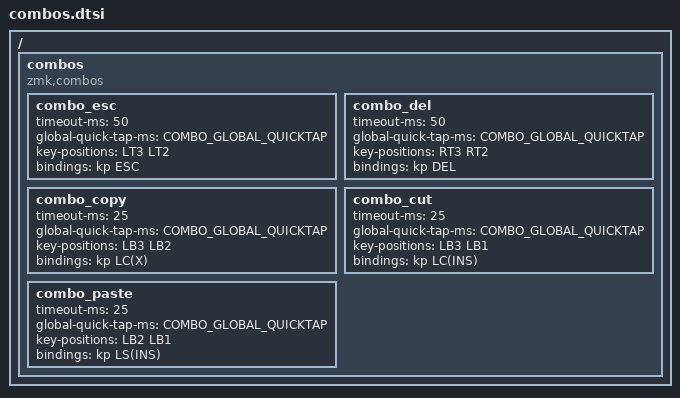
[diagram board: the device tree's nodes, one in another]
#include "../zmk-nodefree-config/keypos_def/keypos_34keys.h"

#define COMBO_GLOBAL_QUICKTAP 100
/ {
  combos {
    compatible = "zmk,combos";
    combo_esc {
      timeout-ms = <50>;
      global-quick-tap-ms = <COMBO_GLOBAL_QUICKTAP>;

      key-positions = <LT3 LT2>;
      bindings = <&kp ESC>;
    };
    combo_del {
      timeout-ms = <50>;
      global-quick-tap-ms = <COMBO_GLOBAL_QUICKTAP>;

      key-positions = <RT3 RT2>;
      bindings = <&kp DEL>;
    };
    combo_copy {
      timeout-ms = <25>;
      global-quick-tap-ms = <COMBO_GLOBAL_QUICKTAP>;

      key-positions = <LB3 LB2>;
      bindings = <&kp LC(X)>;
    };
    combo_cut {
      timeout-ms = <25>;
      global-quick-tap-ms = <COMBO_GLOBAL_QUICKTAP>;

      key-positions = <LB3 LB1>;
      bindings = <&kp LC(INS)>;
    };
    combo_paste {
      timeout-ms = <25>;
      global-quick-tap-ms = <COMBO_GLOBAL_QUICKTAP>;

      key-positions = <LB2 LB1>;
      bindings = <&kp LS(INS)>;
    };
  };
};
